# nrf54h20_sysctrl register map
Vendor: Nordic Semiconductor; Series: nRF54h; File version: 1
Registers are 32-bit, read-write, reset 0x0 unless marked. A register's access mark holds for its fields unless they carry their own. Offsets are from the block's base; [hi:lo] are bit positions; lines under a group give offsets from that group; {n}, {i} and the like mark numbered series; 'fields as' and 'values as' point back to an identical list.

## HFXO — HFXO peripheral
Base 0x5F955000
0x100 EVENTS_MODECHANGED — HFXO mode changed
  [0] EVENTS_MODECHANGED
    0=NotGenerated (Event not generated); 1=Generated (Event generated)
0x104 EVENTS_ERRORPIERCE — Error while starting the HFXO in PIERCE mode
  [0] EVENTS_ERRORPIERCE
    values as EVENTS_MODECHANGED.EVENTS_MODECHANGED
0x108 EVENTS_ERRORRUNNING — Error detected while HFXO was running
  [0] EVENTS_ERRORRUNNING
    values as EVENTS_MODECHANGED.EVENTS_MODECHANGED
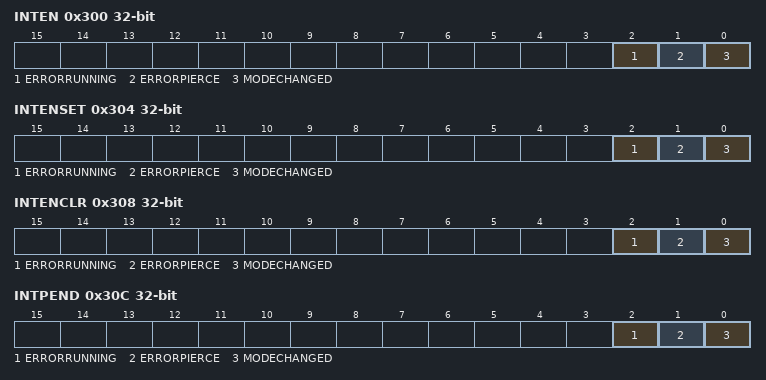
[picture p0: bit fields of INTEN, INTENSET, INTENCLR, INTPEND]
0x300 INTEN — Enable or disable interrupt
  [all] fields
    0=Disabled; 1=Enabled
  [2] ERRORRUNNING — Enable or disable interrupt for event ERRORRUNNING
  [1] ERRORPIERCE — Enable or disable interrupt for event ERRORPIERCE
  [0] MODECHANGED — Enable or disable interrupt for event MODECHANGED
0x304 INTENSET — Enable interrupt
  [all] fields
    on read: 0=Disabled (Read: Disabled); 1=Enabled (Read: Enabled) | on write: 1=Set (Enable)
  [2] ERRORRUNNING — Write '1' to enable interrupt for event ERRORRUNNING
  [1] ERRORPIERCE — Write '1' to enable interrupt for event ERRORPIERCE
  [0] MODECHANGED — Write '1' to enable interrupt for event MODECHANGED
0x308 INTENCLR — Disable interrupt
  [all] fields
    on read: 0=Disabled (Read: Disabled); 1=Enabled (Read: Enabled) | on write: 1=Clear (Disable)
  [2] ERRORRUNNING — Write '1' to disable interrupt for event ERRORRUNNING
  [1] ERRORPIERCE — Write '1' to disable interrupt for event ERRORPIERCE
  [0] MODECHANGED — Write '1' to disable interrupt for event MODECHANGED
0x30C INTPEND ro — Pending interrupts
  [all] fields
    on read: 0=NotPending (Read: Not pending); 1=Pending (Read: Pending)
  [2] ERRORRUNNING — Read pending status of interrupt for event ERRORRUNNING
  [1] ERRORPIERCE — Read pending status of interrupt for event ERRORPIERCE
  [0] MODECHANGED — Read pending status of interrupt for event MODECHANGED
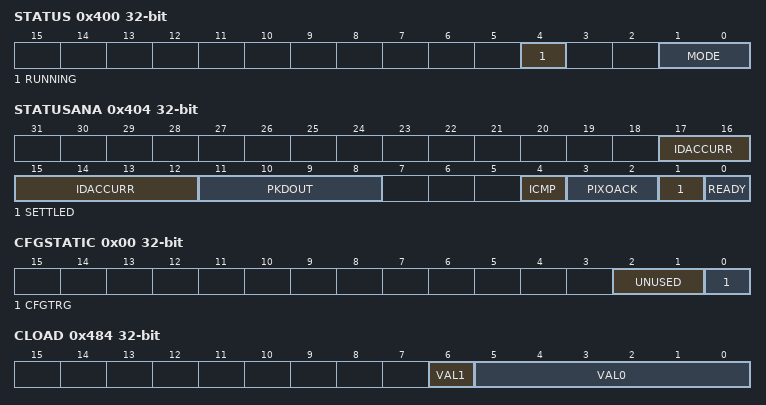
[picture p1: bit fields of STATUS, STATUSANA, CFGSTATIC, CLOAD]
0x400 STATUS ro — HFXO status
  [4] RUNNING — HFXO running status
    0=NotRunning (HFXO not running); 1=Running (HFXO running)
  [1:0] MODE — Current mode
    0=Pierce mode; 1=PIXO mode; 2=External sine wave clock; 3=External square wave clock
0x404 STATUSANA ro — Status of analog module output signals
  [17:12] IDACCURR — Current value of the IDAC_CURR signal to the analog module
  [11:8] PKDOUT — Current value of the PKD_OUT signal from the analog module
  [4] ICMP — Current value of the ICMP signal from the analog module
  [3:2] PIXOACK — Current value of the PIXO_ACK signal from the analog module
  [1] SETTLED — Current value of the SETTLED signal from the analog module
  [0] READY — Current value of the READY signal from the analog module
0x410 CONFIG group — Unspecified
  0x00 CFGSTATIC — HFXO static CFG configuration
    [2:1] UNUSED — Future use
    [0] CFGTRG — Config bus for HFXO32M
      1=Enabled (trigger one-pulse kick-start of XTAL); 0=Disabled (Normal Operation)
0x440 TRIM group — Unspecified
  0x00 AREG — Trim for Pierce AREG mode
    [4:0] VAL — Trimming value for Pierce AREG mode
  0x04 IBIAS — Internal bias generator trim
    [3:0] VAL — Internal bias generator trimming value
  0x08 PIXO — PIXO high pulse supply trim
    [4:0] VAL — Trimming value
  0x0C PDTHR — Peak detector threshold trimming
    [4:0] VAL — Peak detector threshold trimming value
  0x18 VREF — Voltage reference trimming
    [6:0] VAL — Voltage reference trimming value
  0x1C MULT2 — Trimming the duty cycle of the frequency doubler
    [3:0] VAL — Duty cycle of the frequency doubler trimming value
0x480 MIRROR reset 0x1 — Enable LOCK for mirrored registers
  [0] LOCK — Lock for mirrored registers
    0=Disabled (Lock disabled); 1=Enabled (Lock enabled)
0x484 CLOAD — Internal capacitive load
  [6] VAL1 — Capacitive load value 1
  [5:0] VAL0 — Capacitive load value 0
0x488 AMPLITUDECTRL — Amplitude control
  [2:0] VOLT — Voltage amplitude setting for Pierce AREG mode
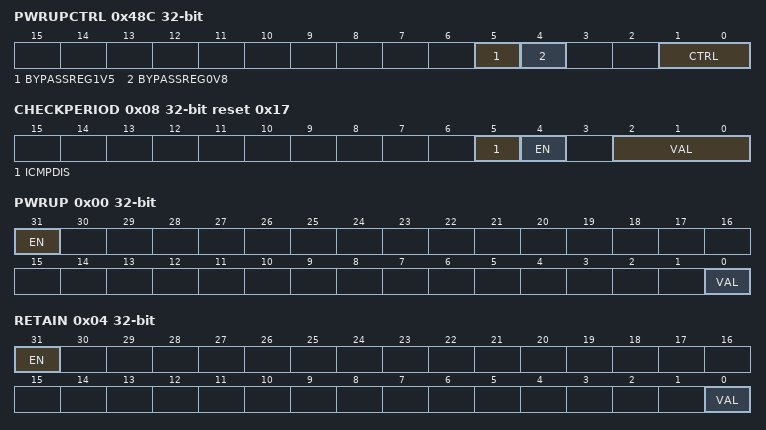
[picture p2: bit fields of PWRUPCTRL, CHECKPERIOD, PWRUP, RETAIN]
0x48C PWRUPCTRL — Power up control
  [5] BYPASSREG1V5 — Bypass 1.5V voltage regulator
    0=Disable (Bypass 1.5V voltage regulator disabled); 1=Enable (Bypass 1.5V voltage regulator enabled)
  [4] BYPASSREG0V8 — Bypass 0.8V voltage regulator
    0=Disable (Bypass 0.8V voltage regulator disabled); 1=Enable (Bypass 0.8V voltage regulator enabled)
  [1:0] CTRL — Power up control
    0=Automatically handled by the peripheral; 1=PowerUp; 2=PowerDown
0x490 MODE — HFXO mode
  [2:0] MODE
    0=Automatically handled by the peripheral; 1=Pierce mode; 2=PIXO mode; 3=External sine wave clock; 4=External square wave clock
0x494 PDTHR reset 0x3 — Peak detector threshold value
  [3:0] VAL — Value
0x498 STARTUPPULSES reset 0x9 — Number of 16MHz clock pulses injected to go into Pierce mode during HFXO startup
  [8:0] VAL — Value
0x49C POWERDOWNWAIT — Enable a 250us wait period in shutdown to allow the crystal to settle down.
  [0] EN — Enable
    0=Disabled (Power down delay disabled); 1=Enabled (Power down delay enabled)
0x4A0 IDAC group — Unspecified
  0x00 INIT — Initial IDAC code for the pierce oscillator. Min = 474nA, default = 114uA, max = 214us
    [3:0] VAL — Value
  0x04 ICMPRATIO — Ratio between IDAC and AREG in the pierce AREG mode
    [1:0] VAL — Value
  0x08 CHECKPERIOD reset 0x17 — Period for the IDAC check in Pierce mode
    [5] ICMPDIS — Disable ICMP alarm.
      0=Enabled (ICMP alarm enabled); 1=Disabled (ICMP alarm disabled)
    [4] EN — Enable IDAC check
      0=Disable (IDAC check disabled); 1=Enable (IDAC check enabled)
    [2:0] VAL — Period value for the IDAC check
      0=val31us (IDAC period is 31us); 1=val61us (IDAC period is 61us); 2=val122us (IDAC period is 122us); 3=val244us (IDAC period is 244us); 4=val488us (IDAC period is 488us); 5=val977us (IDAC period is 977us); 6=val1953us (IDAC period is 1953us); 7=val3906us (IDAC period is 3906us)
  0x0C SETTLETIME reset 0x7 — Settling time for IDAC current changes
    [2:0] VAL — Value
      0=val5us (Settling time is 5us); 1=val10us (Settling time is 10us); 2=val25us (Settling time is 25us); 3=val50us (Settling time is 50us); 4=val100us (Settling time is 100us); 5=val200us (Settling time is 200us); 6=val400us (Settling time is 400us); 7=val800us (Settling time is 800us)
0x500 OVERRIDE group — Unspecified
  0x00 PWRUP — Override the PWRUP signal to the analog module
    [31] EN — Enable the override
      0=Disabled (Override is disabled); 1=Enabled (Override is enabled)
    [0] VAL — Override value for the signal
  0x04 RETAIN — Override the RETAIN signal to the analog module
    fields as OVERRIDE.PWRUP
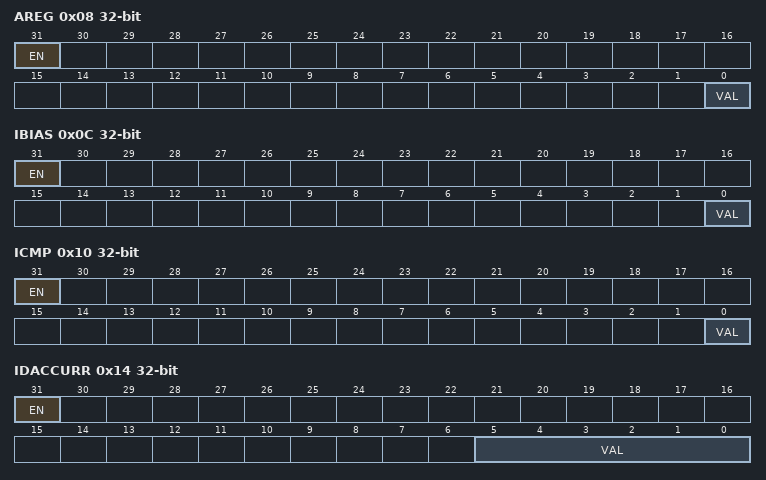
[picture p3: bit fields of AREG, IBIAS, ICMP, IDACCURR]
  0x08 AREG — Override the AREG signal to the analog module
    fields as OVERRIDE.PWRUP
  0x0C IBIAS — Override the IBIAS signal to the analog module
    fields as OVERRIDE.PWRUP
  0x10 ICMP — Override the ICMP signal to the analog module
    fields as OVERRIDE.PWRUP
  0x14 IDACCURR — Override the IDAC_CURR signal to the analog module
    [31] EN — Enable the override
      values as OVERRIDE.PWRUP.EN
    [5:0] VAL — Override value for the signal
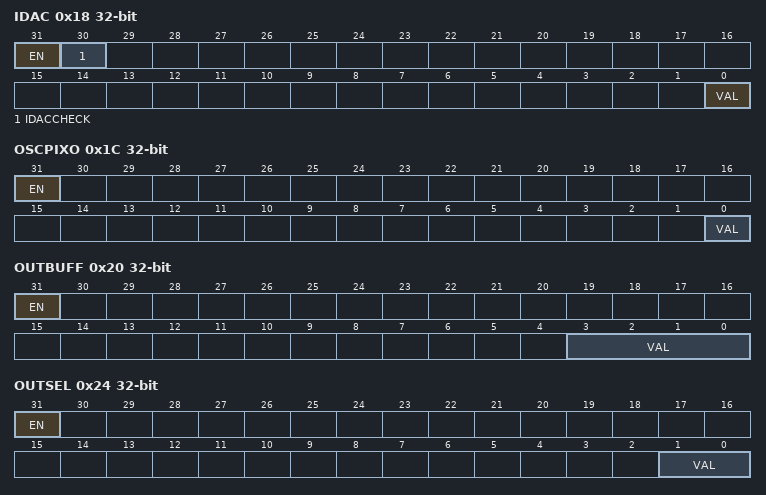
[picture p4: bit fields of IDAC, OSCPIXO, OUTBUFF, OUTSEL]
  0x18 IDAC — Override the IDAC signal to the analog module
    [31] EN — Enable the override
      values as OVERRIDE.PWRUP.EN
    [30] IDACCHECK wo — Task to trigger IDAC check. Note: Triggering is not affected by the override EN bit
      1=Trigger task
    [0] VAL — Override value for the signal
  0x1C OSCPIXO — Override the OSC_PIXO signal to the analog module
    fields as OVERRIDE.PWRUP
  0x20 OUTBUFF — Override the OUT_BUFF signal to the analog module
    [31] EN — Enable the override
      values as OVERRIDE.PWRUP.EN
    [3:0] VAL — Override value for the signal
  0x24 OUTSEL — Override the OUT_SEL signal to the analog module
    [31] EN — Enable the override
      values as OVERRIDE.PWRUP.EN
    [1:0] VAL — Override value for the signal
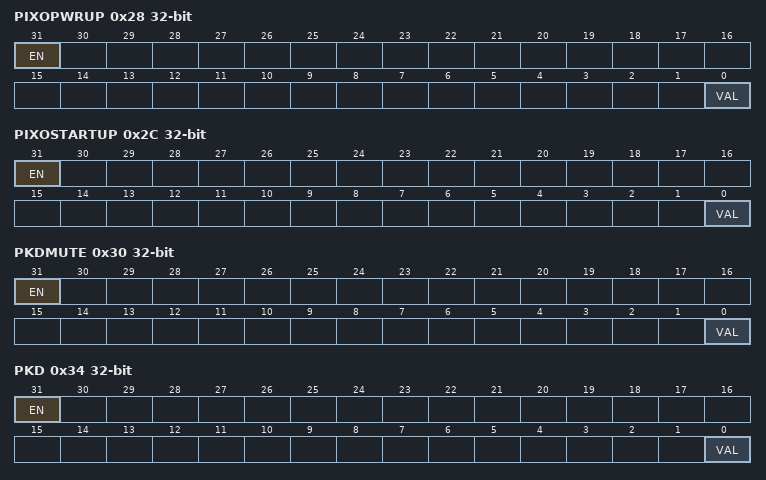
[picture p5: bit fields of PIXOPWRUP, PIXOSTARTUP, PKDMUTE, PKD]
  0x28 PIXOPWRUP — Override the PIXO_PWRUP signal to the analog module
    fields as OVERRIDE.PWRUP
  0x2C PIXOSTARTUP — Override the PIXO_STARTUP signal to the analog module
    fields as OVERRIDE.PWRUP
  0x30 PKDMUTE — Override the PKD_MUTE signal to the analog module
    fields as OVERRIDE.PWRUP
  0x34 PKD — Override the PKD signal to the analog module
    fields as OVERRIDE.PWRUP
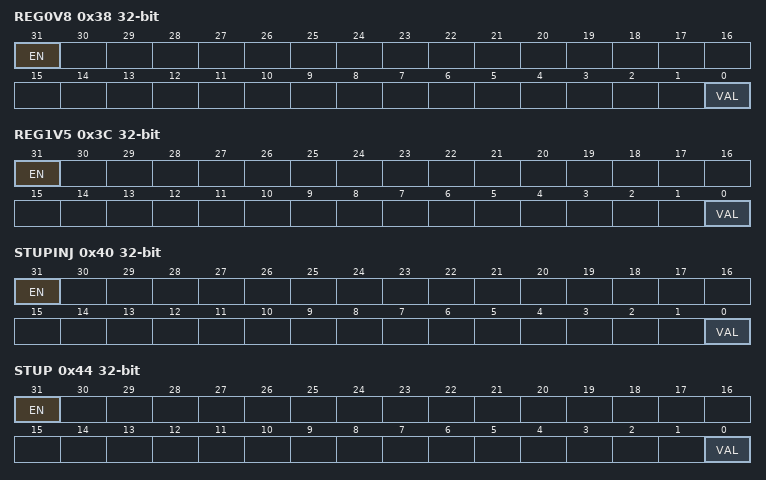
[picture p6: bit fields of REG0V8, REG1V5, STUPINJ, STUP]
  0x38 REG0V8 — Override the REG0V8 signal to the analog module
    fields as OVERRIDE.PWRUP
  0x3C REG1V5 — Override the REG1V5 signal to the analog module
    fields as OVERRIDE.PWRUP
  0x40 STUPINJ — Override the STUP_INJ signal to the analog module
    fields as OVERRIDE.PWRUP
  0x44 STUP — Override the STUP signal to the analog module
    fields as OVERRIDE.PWRUP
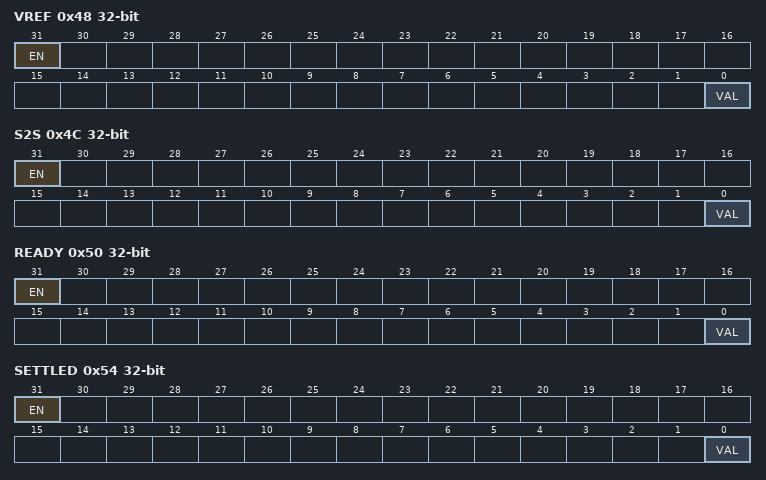
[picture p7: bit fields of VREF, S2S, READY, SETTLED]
  0x48 VREF — Override the VREF signal to the analog module
    fields as OVERRIDE.PWRUP
  0x4C S2S — Override the S2S signal to the analog module
    fields as OVERRIDE.PWRUP
  0x50 READY — Override the READY signal from the analog module
    [31] EN — Enable the override
      values as OVERRIDE.PWRUP.EN
    [0] VAL — Current value of the signal
  0x54 SETTLED — Override the SETTLED signal from the analog module
    fields as OVERRIDE.READY
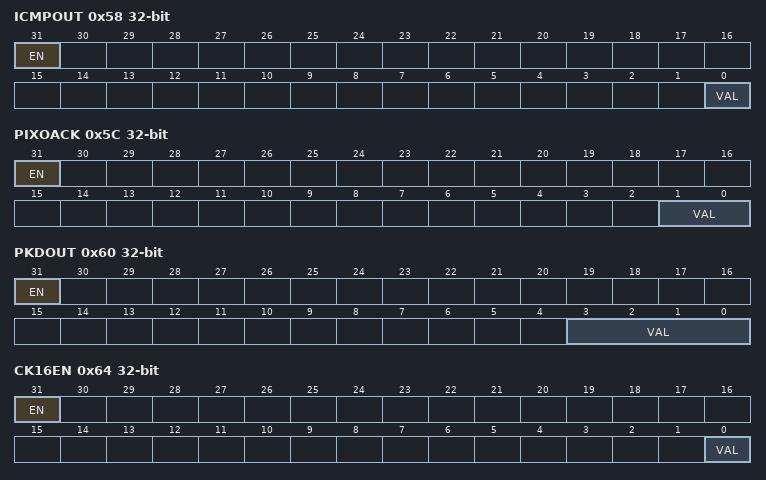
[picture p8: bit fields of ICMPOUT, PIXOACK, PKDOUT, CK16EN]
  0x58 ICMPOUT — Override the ICMP signal from the analog module
    fields as OVERRIDE.READY
  0x5C PIXOACK — Override the PIXO_ACK signal from the analog module
    [31] EN — Enable the override
      values as OVERRIDE.PWRUP.EN
    [1:0] VAL — Current value of the signal
  0x60 PKDOUT — Override the PKD_OUT signal from the analog module
    [31] EN — Enable the override
      values as OVERRIDE.PWRUP.EN
    [3:0] VAL — Current value of the signal
  0x64 CK16EN — Override the MMI's internal 16MHz injection clock enable.
    fields as OVERRIDE.PWRUP
0x600 DFT group — Unspecified
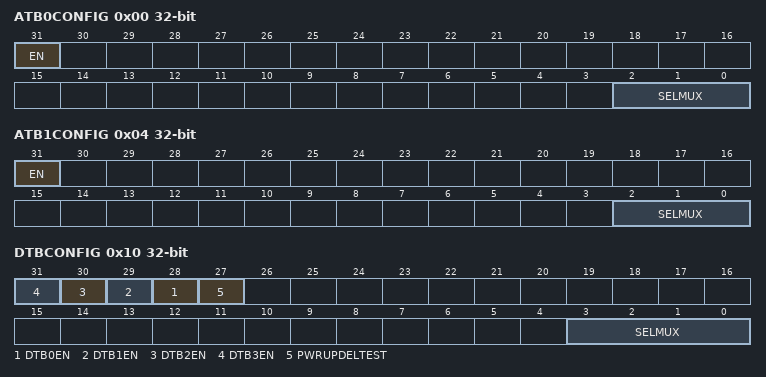
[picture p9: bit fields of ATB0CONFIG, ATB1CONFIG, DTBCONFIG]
  0x00 ATB0CONFIG — Analog Test Bus 0 (ATB0) configuration
    [31] EN — Enable the analog test bus
      0=Disabled (Analog test bus is disabled(HiZ)); 1=Enabled (Analog test bus is enabled)
    [2:0] SELMUX — Select multiplexer for ATB0
      0=None connected; 1=VREGBIASVREF; 2=VDDSWREG1V5; 3=PKDVREF1; 4=FORCEAREGVGN2
  0x04 ATB1CONFIG — Analog Test Bus 1 (ATB1) configuration
    [31] EN — Enable the analog test bus
      values as DFT.ATB0CONFIG.EN
    [2:0] SELMUX — Select multiplexer for ATB1
      0=None connected; 1=VREGBIASVREF; 2=PKDVCM; 3=PIXOHighSupply; 4=IPIERCECPY (IPIERCE_CPY (TCFG to enable IDAC)); 5=PKDVREF4; 6=IBIASIBPP1U; 7=PKDCLOADCAL
  0x10 DTBCONFIG — Digital Test Bus configuration
    [n+28] DTB{n}EN (n=0..3) — Enable digital test bus {n}
      0=Disabled (Digital test bus is disabled); 1=Enabled (Digital test bus is enabled)
    [27] PWRUPDELTEST — Enable the PWRUP delay test circuit
      0=Disabled (PWRUP delay test circuit is disabled); 1=Enabled (PWRUP delay test circuit is enabled)
    [3:0] SELMUX — Select multiplexer for DTB
      {v}=DTBSel{v} (DTB select {v}) (v=0..4)
  0x30 TCFG — Test mode configuration
    [2:0] CONFIG — Configuration
      0=Default (Normal operation); 1=PKDThr50mv (50mV offset for PKD thresholds (not common mode)); 2=Bypass Pierce inverter for AREG calibration; 3=PKDThr100mv (100mV offset for PKD thresholds (not common mode)); 4=IDACATB (Enable IDAC ATB pierce copy output); 5=PXDXC2 (Connect PKD comparator to XC2, for CAPLOAD calibration); 6=Spare; 7=PXDXC2Capload (Connect PKD comparator to XC2, and enable CAPLOAD charge current. For CAPLOAD calibration)
